# STM32MP25_CM33 register map
File version: 1.3
CPU: CM33 r0p1, little endian, MPU, FPU, vendor SysTick, 8 interrupt priority bits
Registers are 32-bit, read-write, reset 0x0 unless marked. A register's access mark holds for its fields unless they carry their own. Offsets are from the block's base; [hi:lo] are bit positions; {n}, {i} and the like mark numbered series; 'fields as' and 'values as' point back to an identical list.

## IAC — IAC register block
Base 0x42090000
Same registers: IAC_S 0x52090000
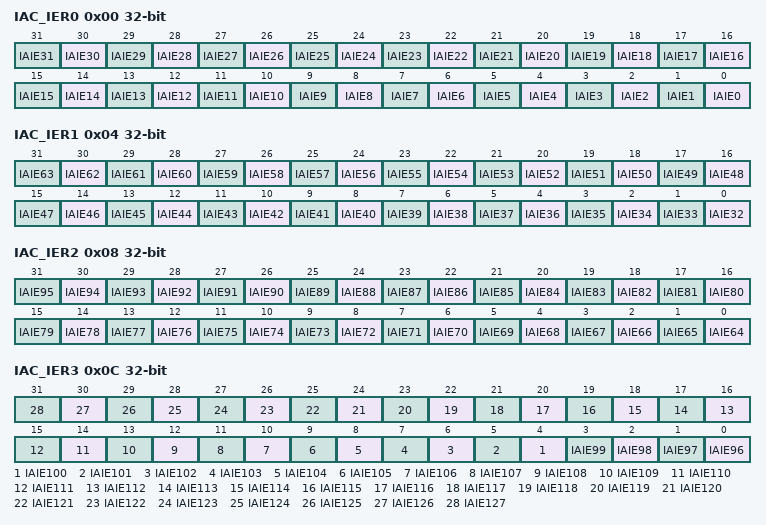
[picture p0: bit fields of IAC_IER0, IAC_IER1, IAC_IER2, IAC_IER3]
0x00 IAC_IER0 — IAC interrupt enable register 0
  [n] IAIE{n} (n=0..31) — Illegal access interrupt enable for peripheral {n} Each bit is set to unmask illegal access events from peripheral {n}.
    0=Illegal access event from peripheral {n} does not generate interrupt (masked); 1=Illegal access event from peripheral {n} can generate interrupts (unmasked)
0x04 IAC_IER1 — IAC interrupt enable register 1
  [n-32] IAIE{n} (n=32..63) — Illegal access interrupt enable for peripheral {n} Each bit is set to unmask illegal access events from peripheral {n}.
    values as IAC_IER0.IAIE0
0x08 IAC_IER2 — IAC interrupt enable register 2
  [n-64] IAIE{n} (n=64..95) — Illegal access interrupt enable for peripheral {n} Each bit is set to unmask illegal access events from peripheral {n}.
    values as IAC_IER0.IAIE0
0x0C IAC_IER3 — IAC interrupt enable register 3
  [n-96] IAIE{n} (n=96..127) — Illegal access interrupt enable for peripheral {n} Each bit is set to unmask illegal access events from peripheral {n}.
    values as IAC_IER0.IAIE0
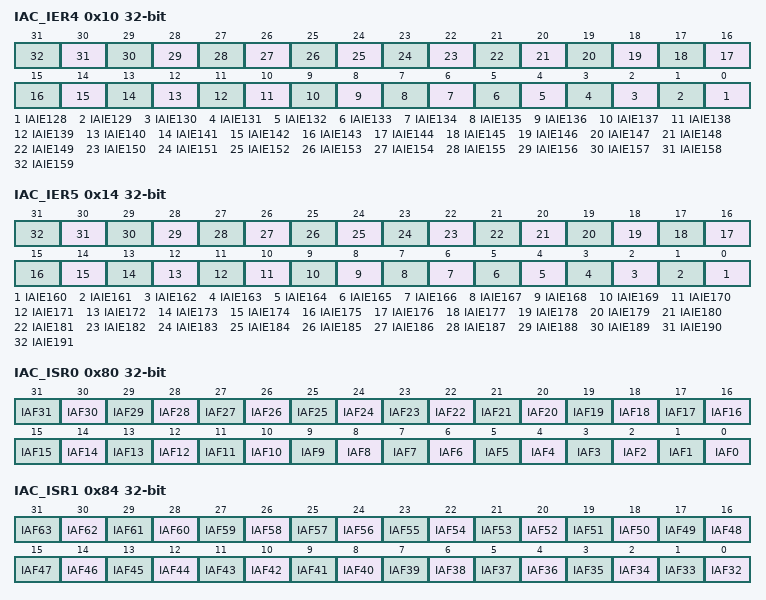
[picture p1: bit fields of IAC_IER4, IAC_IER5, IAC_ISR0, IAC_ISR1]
0x10 IAC_IER4 — IAC interrupt enable register 4
  [n-128] IAIE{n} (n=128..159) — Illegal access interrupt enable for peripheral {n} Each bit is set to unmask illegal access events from peripheral {n}.
    values as IAC_IER0.IAIE0
0x14 IAC_IER5 — IAC interrupt enable register 5
  [n-160] IAIE{n} (n=160..191) — Illegal access interrupt enable for peripheral {n} Each bit is set to unmask illegal access events from peripheral {n}.
    values as IAC_IER0.IAIE0
0x80 IAC_ISR0 ro — IAC interrupt status register 0
  [n] IAF{n} (n=0..31) — Illegal access interrupt enable for peripheral {n} Each bit is set when an illegal access event occurs in the peripheral {n} (see Section11.3 for details). This bit is cleared when the corresponding IAF bit is set in IAC_ICRx.
    0=No illegal access event detected for peripheral {n} (since reset or the last time this bit was cleared); 1=At least one illegal access event has been detected for peripheral {n} (since the last time this bit was cleared)
0x84 IAC_ISR1 ro — IAC interrupt status register 1
  [n-32] IAF{n} (n=32..63) — Illegal access interrupt enable for peripheral {n} Each bit is set when an illegal access event occurs in the peripheral {n} (see Section11.3 for details). This bit is cleared when the corresponding IAF bit is set in IAC_ICRx.
    values as IAC_ISR0.IAF0
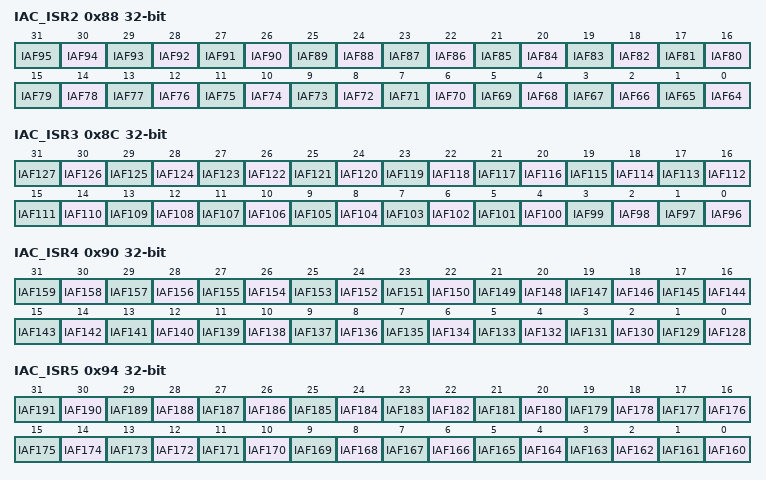
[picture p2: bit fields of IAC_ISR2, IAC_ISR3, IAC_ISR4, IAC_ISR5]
0x88 IAC_ISR2 ro — IAC interrupt status register 2
  [n-64] IAF{n} (n=64..95) — Illegal access interrupt enable for peripheral {n} Each bit is set when an illegal access event occurs in the peripheral {n} (see Section11.3 for details). This bit is cleared when the corresponding IAF bit is set in IAC_ICRx.
    values as IAC_ISR0.IAF0
0x8C IAC_ISR3 ro — IAC interrupt status register 3
  [n-96] IAF{n} (n=96..127) — Illegal access interrupt enable for peripheral {n} Each bit is set when an illegal access event occurs in the peripheral {n} (see Section11.3 for details). This bit is cleared when the corresponding IAF bit is set in IAC_ICRx.
    values as IAC_ISR0.IAF0
0x90 IAC_ISR4 ro — IAC interrupt status register 4
  [n-128] IAF{n} (n=128..159) — Illegal access interrupt enable for peripheral {n} Each bit is set when an illegal access event occurs in the peripheral {n} (see Section11.3 for details). This bit is cleared when the corresponding IAF bit is set in IAC_ICRx.
    values as IAC_ISR0.IAF0
0x94 IAC_ISR5 ro — IAC interrupt status register 5
  [n-160] IAF{n} (n=160..191) — Illegal access interrupt enable for peripheral {n} Each bit is set when an illegal access event occurs in the peripheral {n} (see Section11.3 for details). This bit is cleared when the corresponding IAF bit is set in IAC_ICRx.
    values as IAC_ISR0.IAF0
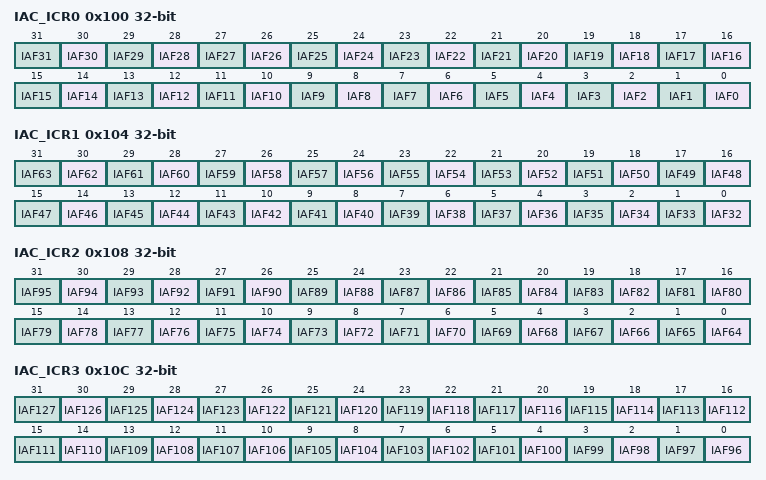
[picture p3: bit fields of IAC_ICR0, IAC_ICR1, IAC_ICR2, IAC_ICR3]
0x100 IAC_ICR0 wo — IAC interrupt clear register 0
  [n] IAF{n} (n=0..31) — Illegal access flag clear for peripheral {n} Setting each bit clears the status flag of the illegal access event {n} in IAC_ISRx.
    0=IAF {n} flag status not affected; 1=IAF {n} flag status cleared in IAC_ISRx
0x104 IAC_ICR1 wo — IAC interrupt clear register 1
  [n-32] IAF{n} (n=32..63) — Illegal access flag clear for peripheral {n} Setting each bit clears the status flag of the illegal access event {n} in IAC_ISRx.
    values as IAC_ICR0.IAF0
0x108 IAC_ICR2 wo — IAC interrupt clear register 2
  [n-64] IAF{n} (n=64..95) — Illegal access flag clear for peripheral {n} Setting each bit clears the status flag of the illegal access event {n} in IAC_ISRx.
    values as IAC_ICR0.IAF0
0x10C IAC_ICR3 wo — IAC interrupt clear register 3
  [n-96] IAF{n} (n=96..127) — Illegal access flag clear for peripheral {n} Setting each bit clears the status flag of the illegal access event {n} in IAC_ISRx.
    values as IAC_ICR0.IAF0
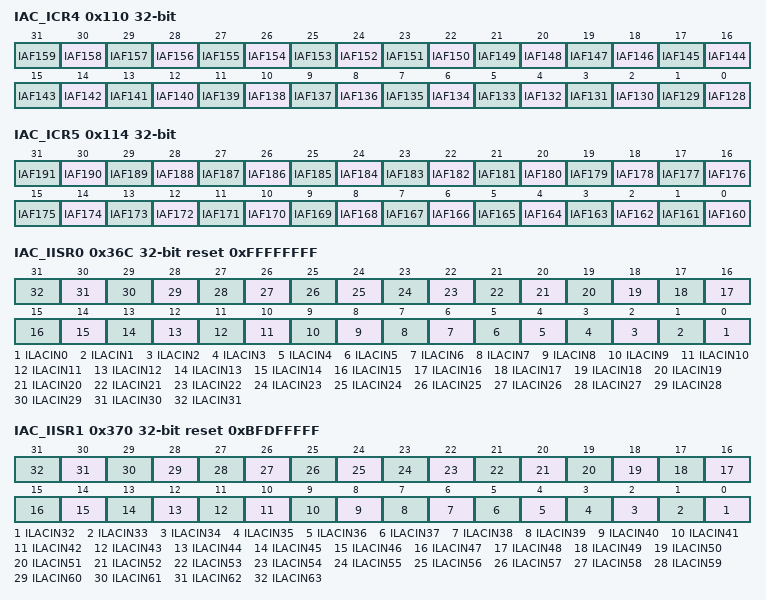
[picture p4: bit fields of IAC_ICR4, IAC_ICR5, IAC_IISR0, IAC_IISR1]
0x110 IAC_ICR4 wo — IAC interrupt clear register 4
  [n-128] IAF{n} (n=128..159) — Illegal access flag clear for peripheral {n} Setting each bit clears the status flag of the illegal access event {n} in IAC_ISRx.
    values as IAC_ICR0.IAF0
0x114 IAC_ICR5 wo — IAC interrupt clear register 5
  [n-160] IAF{n} (n=160..191) — Illegal access flag clear for peripheral {n} Setting each bit clears the status flag of the illegal access event {n} in IAC_ISRx.
    values as IAC_ICR0.IAF0
0x36C IAC_IISR0 ro reset 0xFFFFFFFF — IAC ILAC input status register 0
  [n] ILACIN{n} (n=0..31) — Illegal access input {n}
    0=ILAC input {n} to IAC not present; 1=ILAC input {n} to IAC present
0x370 IAC_IISR1 ro reset 0xBFDFFFFF — IAC ILAC input status register 1
  [n-32] ILACIN{n} (n=32..63) — Illegal access input {n}
    values as IAC_IISR0.ILACIN0
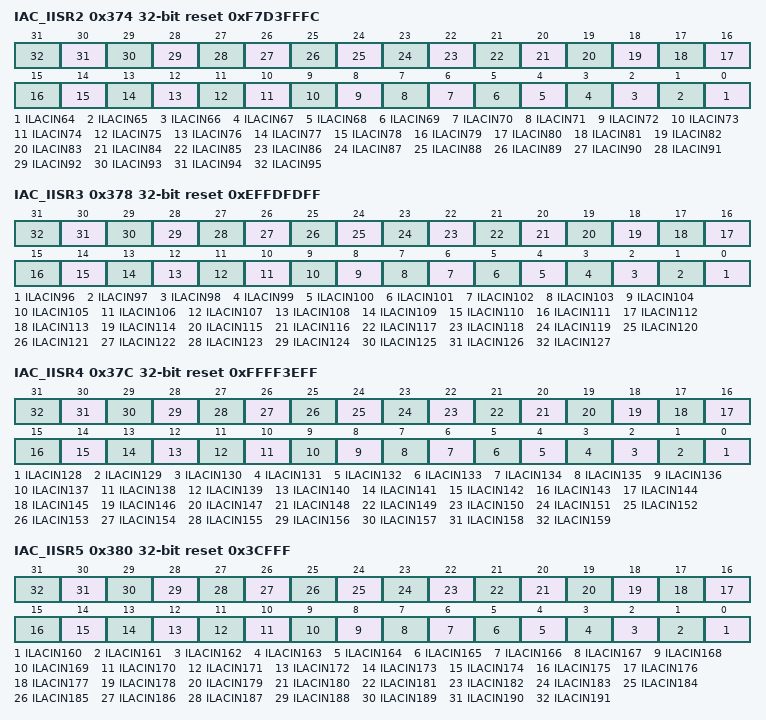
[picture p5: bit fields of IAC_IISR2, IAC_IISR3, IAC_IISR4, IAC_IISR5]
0x374 IAC_IISR2 ro reset 0xF7D3FFFC — IAC ILAC input status register 2
  [n-64] ILACIN{n} (n=64..95) — Illegal access input {n}
    values as IAC_IISR0.ILACIN0
0x378 IAC_IISR3 ro reset 0xEFFDFDFF — IAC ILAC input status register 3
  [n-96] ILACIN{n} (n=96..127) — Illegal access input {n}
    values as IAC_IISR0.ILACIN0
0x37C IAC_IISR4 ro reset 0xFFFF3EFF — IAC ILAC input status register 4
  [n-128] ILACIN{n} (n=128..159) — Illegal access input {n}
    values as IAC_IISR0.ILACIN0
0x380 IAC_IISR5 ro reset 0x3CFFF — IAC ILAC input status register 5
  [n-160] ILACIN{n} (n=160..191) — Illegal access input {n}
    values as IAC_IISR0.ILACIN0
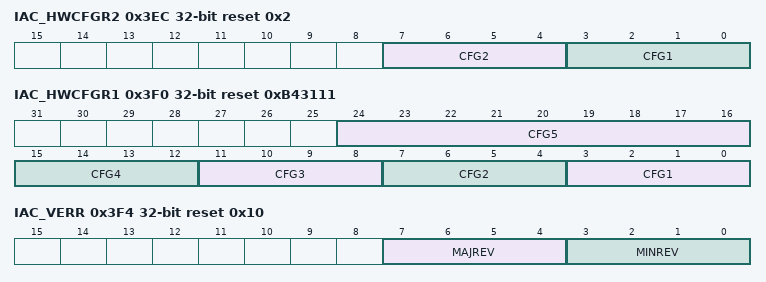
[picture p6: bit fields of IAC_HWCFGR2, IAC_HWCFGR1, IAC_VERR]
0x3EC IAC_HWCFGR2 ro reset 0x2 — IAC hardware configuration register 2
  [7:4] CFG2 — Hardware configuration 2 This bit field returns the generic value DEFAULT_IER.
  [3:0] CFG1 — Hardware configuration 1 This bit field returns the generic value NUM_RESYNC_FLOPS.
0x3F0 IAC_HWCFGR1 ro reset 0xB43111 — IAC hardware configuration register 1
  [24:16] CFG5 — Hardware configuration 5 This bit field returns the generic value NUM_ILAC.
  [15:12] CFG4 — Hardware configuration 4 This bit field returns the generic value CID_WIDTH.
  [11:8] CFG3 — Hardware configuration 3 This bit field returns the generic value PRIV_ENABLED.
  [7:4] CFG2 — Hardware configuration 2 This bit field returns the generic value SEC_ENABLED.
  [3:0] CFG1 — Hardware configuration 1 This bit field returns the generic value RIF_ENABLED.
0x3F4 IAC_VERR ro reset 0x10 — IAC version register
  [7:4] MAJREV — IAC major revision
  [3:0] MINREV — IAC minor revision
0x3F8 IAC_IPIDR ro reset 0x100163 — IAC identification register
  [31:0] ID — IAC identification code
0x3FC IAC_SIDR ro reset 0xA3C5DD01 — IAC size identification register
  [31:0] SID — IAC size identification code Bits[31:8] = 0xA3C5DD (fixed code) Bits[7:0] = 0x01 (1-Kbyte address decoding)
